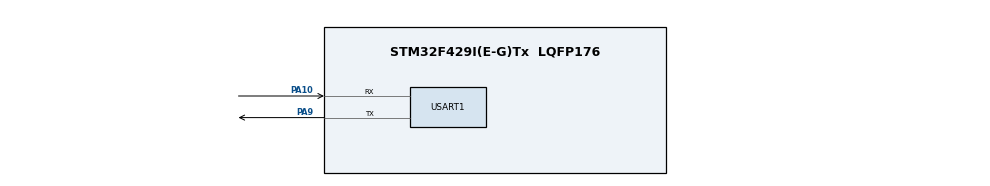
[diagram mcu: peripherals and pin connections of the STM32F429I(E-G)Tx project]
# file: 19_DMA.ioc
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Dma.Request0=USART1_TX
Dma.USART1_TX.0.Direction=DMA_MEMORY_TO_PERIPH
Dma.USART1_TX.0.FIFOMode=DMA_FIFOMODE_DISABLE
Dma.USART1_TX.0.Instance=DMA2_Stream7
Dma.USART1_TX.0.MemDataAlignment=DMA_MDATAALIGN_BYTE
Dma.USART1_TX.0.MemInc=DMA_MINC_ENABLE
Dma.USART1_TX.0.Mode=DMA_NORMAL
Dma.USART1_TX.0.PeriphDataAlignment=DMA_PDATAALIGN_BYTE
Dma.USART1_TX.0.PeriphInc=DMA_PINC_DISABLE
Dma.USART1_TX.0.Priority=DMA_PRIORITY_MEDIUM
Mcu.Family=STM32F4
Mcu.Name=STM32F429I(E-G)Tx
Mcu.Package=LQFP176
NVIC.DMA2_Stream7_IRQn=true\:0\:0\:false\:false\:true\:false\:true
NVIC.PriorityGroup=NVIC_PRIORITYGROUP_4
NVIC.USART1_IRQn=true\:0\:0\:false\:false\:true\:true\:true
PA10.Mode=Asynchronous
PA10.Signal=USART1_RX
PA13.Mode=Trace_Asynchronous_SW
PA13.Signal=SYS_JTMS-SWDIO
PA14.Mode=Trace_Asynchronous_SW
PA14.Signal=SYS_JTCK-SWCLK
PA9.Mode=Asynchronous
PA9.Signal=USART1_TX
PB3.Mode=Trace_Asynchronous_SW
PB3.Signal=SYS_JTDO-SWO
PC14/OSC32_IN.Mode=LSE-External-Oscillator
PC14/OSC32_IN.Signal=RCC_OSC32_IN
PC15/OSC32_OUT.Mode=LSE-External-Oscillator
PC15/OSC32_OUT.Signal=RCC_OSC32_OUT
PH0/OSC_IN.Mode=HSE-External-Oscillator
PH0/OSC_IN.Signal=RCC_OSC_IN
PH1/OSC_OUT.Mode=HSE-External-Oscillator
PH1/OSC_OUT.Signal=RCC_OSC_OUT
ProjectManager.HeapSize=0x200
ProjectManager.StackSize=0x400
ProjectManager.TargetToolchain=STM32CubeIDE
RCC.48MHZClocksFreq_Value=90000000
RCC.AHBFreq_Value=180000000
RCC.APB1CLKDivider=RCC_HCLK_DIV4
RCC.APB1Freq_Value=45000000
RCC.APB1TimFreq_Value=90000000
RCC.APB2CLKDivider=RCC_HCLK_DIV2
RCC.APB2Freq_Value=90000000
RCC.APB2TimFreq_Value=180000000
RCC.CortexFreq_Value=180000000
RCC.HCLKFreq_Value=180000000
RCC.HSE_VALUE=25000000
RCC.HSI_VALUE=16000000
RCC.PLLM=15
RCC.PLLN=216
RCC.PLLSourceVirtual=RCC_PLLSOURCE_HSE
RCC.SYSCLKFreq_VALUE=180000000
RCC.SYSCLKSource=RCC_SYSCLKSOURCE_PLLCLK
RCC.VCOOutputFreq_Value=360000000
USART1.VirtualMode=VM_ASYNC
board=custom

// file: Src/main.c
/* USER CODE BEGIN Header */
/**
 ******************************************************************************
 * @file           : main.c
 * @brief          : Main program body
 ******************************************************************************
 * @attention
 *
 * <h2><center>&copy; Copyright (c) 2019 STMicroelectronics.
 * All rights reserved.</center></h2>
 *
 * This software component is licensed by ST under BSD 3-Clause license,
 * the "License"; You may not use this file except in compliance with the
 * License. You may obtain a copy of the License at:
 *                        opensource.org/licenses/BSD-3-Clause
 *
 ******************************************************************************
 */
/* USER CODE END Header */

#include "main.h"
#include "dma.h"
#include "usart.h"
#include "gpio.h"

/* USER CODE BEGIN Includes */
#include <stdio.h>
/* USER CODE END Includes */

/* USER CODE BEGIN PD */
#define SEND_BUF_SIZE 140000

/* USER CODE END PD */

/* USER CODE BEGIN PV */
uint8_t sendMsg[] = { "12345678900\r\n" }; // size = 14
uint8_t sendBuf[SEND_BUF_SIZE] = { }; // size = 14000
int reming = 0;
int flag = 0;
int dma_flag = 0;
int busy_flag = 0;

uint32_t start_time = 0;
volatile uint32_t current_Time = 0;
volatile cpt_flag = 0;
uint32_t DMA_time = 0;
uint32_t IT_time = 0;

/* USER CODE END PV */

void SystemClock_Config (void);

int main (void)
{

    /* MCU Configuration--------------------------------------------------------*/

    /* Reset of all peripherals, Initializes the Flash interface and the Systick. */
    HAL_Init ();

    /* Configure the system clock */
    SystemClock_Config ();

    /* Initialize all configured peripherals */
    MX_GPIO_Init ();
    MX_DMA_Init ();
    MX_USART1_UART_Init ();
    /* USER CODE BEGIN 2 */
    printf ("Start\r\n");

    int t = SEND_BUF_SIZE / sizeof(sendMsg);
    int k = 0;
    for (int i = 0; i < t; i++)
    {
	for (int j = 0; j < 14; j++)
	{
	    sendBuf[k++] = sendMsg[j];
	}
    }
    start_time = HAL_GetTick ();
    HAL_UART_Transmit_DMA (&huart1, sendBuf, SEND_BUF_SIZE);

    //HAL_DMA_Start(huart1.hdmatx, (uint32_t)sendBuf, (uint32_t)&huart1.Instance->DR, SEND_BUF_SIZE);
    //huart1.Instance->CR3 |= USART_CR3_DMAT;

//    reming = __HAL_DMA_GET_COUNTER(&hdma_usart1_tx);
//    while (reming)
//    {
//	reming = __HAL_DMA_GET_COUNTER(&hdma_usart1_tx);
//	dma_flag = __HAL_DMA_GET_FLAG(&hdma_usart1_tx, DMA_FLAG_TCIF3_7);
//    }

    while(cpt_flag == 0);
    DMA_time = current_Time - start_time;
    cpt_flag = 0;

    start_time = HAL_GetTick ();
    HAL_UART_Transmit_IT (&huart1, sendBuf, SEND_BUF_SIZE);
//    while(HAL_UART_GetState(&huart1) == HAL_UART_STATE_BUSY);
    while(cpt_flag == 0);
    IT_time = current_Time - start_time;
    /* USER CODE END 2 */

    /* Infinite loop */
    /* USER CODE BEGIN WHILE */
    while (1)
    {

//	if(dma_flag)
//	{
//	    flag = 5000;
//	}else if(reming  == 0)
//	{
//	    flag = 2500;
//	}
	/* USER CODE END WHILE */

    }
}

void SystemClock_Config (void)
{
    RCC_OscInitTypeDef RCC_OscInitStruct = { 0 };
    RCC_ClkInitTypeDef RCC_ClkInitStruct = { 0 };

    /** Configure the main internal regulator output voltage
     */
    __HAL_RCC_PWR_CLK_ENABLE();
    __HAL_PWR_VOLTAGESCALING_CONFIG(PWR_REGULATOR_VOLTAGE_SCALE1);
    /** Initializes the CPU, AHB and APB busses clocks
     */
    RCC_OscInitStruct.OscillatorType = RCC_OSCILLATORTYPE_HSE;
    RCC_OscInitStruct.HSEState = RCC_HSE_ON;
    RCC_OscInitStruct.PLL.PLLState = RCC_PLL_ON;
    RCC_OscInitStruct.PLL.PLLSource = RCC_PLLSOURCE_HSE;
    RCC_OscInitStruct.PLL.PLLM = 15;
    RCC_OscInitStruct.PLL.PLLN = 216;
    RCC_OscInitStruct.PLL.PLLP = RCC_PLLP_DIV2;
    RCC_OscInitStruct.PLL.PLLQ = 4;
    if (HAL_RCC_OscConfig (&RCC_OscInitStruct) != HAL_OK)
    {
	Error_Handler ();
    }
    /** Activate the Over-Drive mode
     */
    if (HAL_PWREx_EnableOverDrive () != HAL_OK)
    {
	Error_Handler ();
    }
    /** Initializes the CPU, AHB and APB busses clocks
     */
    RCC_ClkInitStruct.ClockType = RCC_CLOCKTYPE_HCLK | RCC_CLOCKTYPE_SYSCLK | RCC_CLOCKTYPE_PCLK1 | RCC_CLOCKTYPE_PCLK2;
    RCC_ClkInitStruct.SYSCLKSource = RCC_SYSCLKSOURCE_PLLCLK;
    RCC_ClkInitStruct.AHBCLKDivider = RCC_SYSCLK_DIV1;
    RCC_ClkInitStruct.APB1CLKDivider = RCC_HCLK_DIV4;
    RCC_ClkInitStruct.APB2CLKDivider = RCC_HCLK_DIV2;

    if (HAL_RCC_ClockConfig (&RCC_ClkInitStruct, FLASH_LATENCY_5) != HAL_OK)
    {
	Error_Handler ();
    }
}

/* USER CODE BEGIN 4 */

int _write (int file,char*ptr,int len)
{
    int DataIdx;
    for (DataIdx = 0; DataIdx < len; DataIdx++)
    {
	ITM_SendChar (*ptr++);
    }
    return len;
}

void HAL_UART_TxCpltCallback (UART_HandleTypeDef*huart)
{
    if (huart->Instance == huart1.Instance)
    {
	//HAL_UART_DMAStop(&huart1);
	current_Time = HAL_GetTick ();
	cpt_flag = 1;
    }
}
void HAL_UART_TxHalfCpltCallback (UART_HandleTypeDef*huart)
{
    if (huart->Instance == huart1.Instance)
    {
    }
}

/* USER CODE END 4 */

void Error_Handler (void)
{
}

/************************ (C) COPYRIGHT STMicroelectronics *****END OF FILE****/
